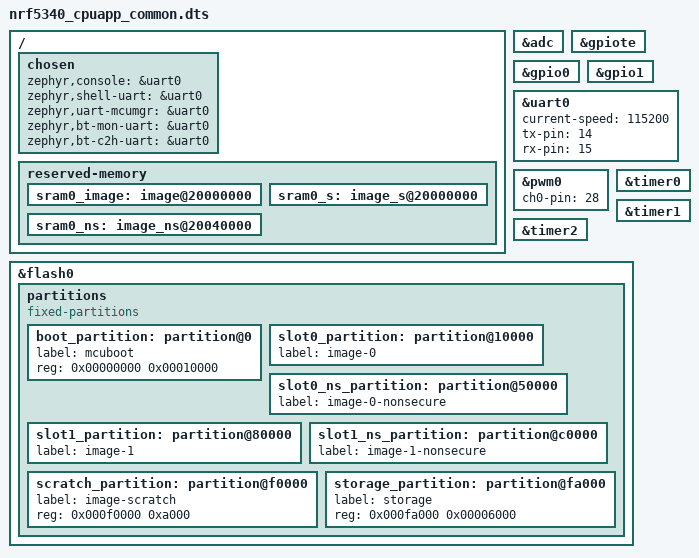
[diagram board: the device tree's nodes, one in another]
/*
 * Copyright (c) 2019-2020 Nordic Semiconductor ASA
 *
 * SPDX-License-Identifier: Apache-2.0
 */

/ {

	chosen {
		zephyr,console = &uart0;
		zephyr,shell-uart = &uart0;
		zephyr,uart-mcumgr = &uart0;
		zephyr,bt-mon-uart = &uart0;
		zephyr,bt-c2h-uart = &uart0;
	};

};

&adc {
	status = "okay";
};

&gpiote {
	status = "okay";
};

&gpio0 {
	status = "okay";
};

&gpio1 {
	status = "okay";
};

&uart0 {
	/* Not connected to anything.
	*  Can use GPIOs P1.02 and P0.09 but shared with SW2 and SW3 */
	status = "okay";
	current-speed = <115200>;
	tx-pin = <14>;
	rx-pin = <15>;
};

&pwm0 {
	status = "okay";
	ch0-pin = <28>;
};

&timer0 {
	status = "okay";
};

&timer1 {
	status = "okay";
};

&timer2 {
	status = "okay";
};

&flash0 {

	partitions {
		compatible = "fixed-partitions";
		#address-cells = <1>;
		#size-cells = <1>;

		boot_partition: partition@0 {
			label = "mcuboot";
			reg = <0x00000000 0x00010000>;
		};
		slot0_partition: partition@10000 {
			label = "image-0";
		};
		slot0_ns_partition: partition@50000 {
			label = "image-0-nonsecure";
		};
		slot1_partition: partition@80000 {
			label = "image-1";
		};
		slot1_ns_partition: partition@c0000 {
			label = "image-1-nonsecure";
		};
		scratch_partition: partition@f0000 {
			label = "image-scratch";
			reg = <0x000f0000 0xa000>;
		};
		storage_partition: partition@fa000 {
			label = "storage";
			reg = <0x000fa000 0x00006000>;
		};
	};
};

/ {

	reserved-memory {
		#address-cells = <1>;
		#size-cells = <1>;
		ranges;

		sram0_image: image@20000000 {
			/* Zephyr image(s) memory */
		};

		sram0_s: image_s@20000000 {
			/* Secure image memory */
		};

		sram0_ns: image_ns@20040000 {
			/* Non-Secure image memory */
		};
	};
};

/* Include partition configuration file */
#include "nrf5340_cpuapp_partition_conf.dts"
